# psoc4100tp register map
Vendor: Infineon Technologies; Series: PSOC4100Tp; File version: 1.0
CPU: CM0PLUS r0p1, little endian, no MPU, no FPU, VTOR, 2 interrupt priority bits
Registers are 32-bit, read-write, reset 0x0 unless marked. A register's access mark holds for its fields unless they carry their own. Offsets are from the block's base; [hi:lo] are bit positions; lines under a group give offsets from that group; {n}, {i} and the like mark numbered series; 'fields as' and 'values as' point back to an identical list; <NAME> marks a mode.

## MSCLP0 — Low Power MultiSense Converter
Base 0x40290000
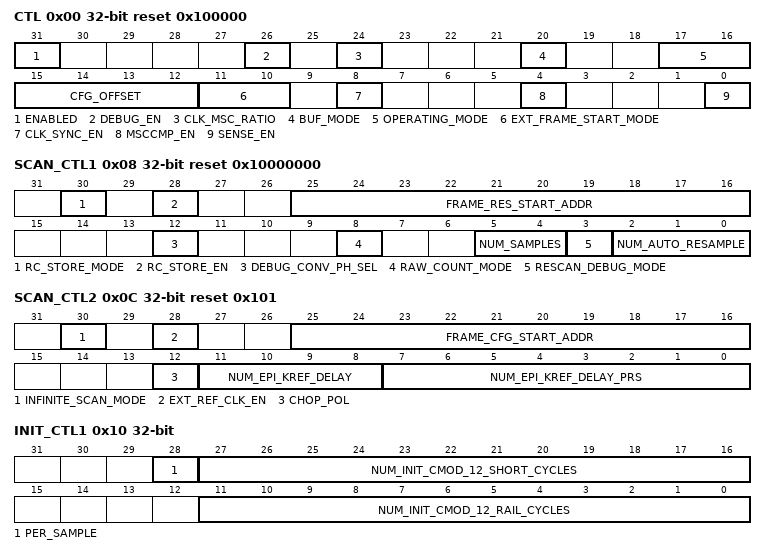
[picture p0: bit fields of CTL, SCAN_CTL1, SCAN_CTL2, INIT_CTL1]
0x00 CTL reset 0x100000 — Configuration and Control
  [31] ENABLED — Master enable of the MSCLP IP. Must be set to '1' for any operation to function. When '0' all analog components are off and all switches are open.
    0=DISABLED (N/A); 1=ENABLED (N/A)
  [26] DEBUG_EN
    0=DISABLED (N/A); 1=ENABLED (N/A)
  [24] CLK_MSC_RATIO — Control bit for logic that creates clk_msc from clk_hf. '0': Divided. clk_hf :: clk_msc is at least 2:1 divide ratio. Ratio controlled by clock_msc_pos_en and clock_msc_neg_en provided by PERI. '1': Pass-through. clk_hf :: clk_msc is 1:1.
    0=DIVIDED (N/A); 1=PASSTHROUGH (N/A)
  [20] BUF_MODE
    0=HIGH_BW_MODE (N/A); 1=SHIELD_MODE (N/A)
  [17:16] OPERATING_MODE
    0=CPU (Frame scan configurations are stored in system RAM. Start of frame initiated by CPU via AHB (typically using FRAME_CMD.START_FRAME) or an external frame start. After each scan in frame, the end of scan interrupt is raised. The CPU extracts results and programs and starts the next scan. ...); 1=CS_DMA (Frame scan configurations are stored in system RAM. Start of frame is initiated by CPU via AHB (typically using FRAME_CMD.START_FRAME) or an external frame start. MSCv3LP requests DMA to write each scan configuration and read each scan result....); 2=AS_MS (Frame scan configurations are stored in IP RAM. Start of frame initiated by CPU via AHB (expected to be FRAME_CMD.START_FRAME) or an external frame start. All of the scans in the frame are chained autonomously by Sequencer FSM. ...); 3=LP_AOS (Frame scan configurations are stored in IP RAM. Start of frame initiated by CPU via AHB (expected to be WAKEUP_CMD.START_FRAME_AOS) or an external frame start, and first frame starts after LP-AoS timer expire (as defined by WAKEUP_TIMER). Each scan in frame is chained autonomously by Sequencer FSM....)
  [15:12] CFG_OFFSET — Starting 32-bit word address offset index from SNS_LP_AOS_SNS_CTL0 register for each sensor configuration structure in local IP storage SENSOR_DATA. The difference between this CFG_OFFSET index and the index of SNS_CTL (index of 0xd addresses from SNS_LP_AOS_SNS_CTL0) defines the size of each configuration structure in SENSOR_DATA and the group of registers that change autonomously from sensor to sensor when scanning in AS_MS or LP_AOS modes. This setting is used by hardware when reading from local memory and programming IP registers - the logic will load from the memory from this starting offset and store into the SNS_* registers up to and including SNS_CTL. For example, setting this value to 0xb means that each configuration structure starts from SNS_SCAN_CTL (and all SNS_* registers up to and including SNS_CTL, so the configuration structure in SENSOR_DATA is 3x 32-bit words per sensor). Firmware Rule: If using AS_MS/LP_AOS mode and engaging the Channel Engine (CE_CTL.ENABLED = 1), then CFG_OFFSET must be set to 0x0 since the Channel Engine related registers are offset from here (SNS_LP_AOS_SENSOR_CTL0).
  [11:10] EXT_FRAME_START_MODE — Control to enable external frame start via GPIO. '0': External frame start capability off. Only START_FRAME or START_FRAME_AOS may be used to start frames. '1': External frame start capability on for frames where firmware is responsible for enabling MRSS. '2': External frame start capability on for low power frame where hardware is responsible for enabling MRSS.
    0=DISABLED (N/A); 1=EXT_FRAME_SCAN (N/A); 2=EXT_FRAME_LP_SCAN (N/A)
  [8] CLK_SYNC_EN — Control bit to create external channel sync clock. Used for multi-chip operation. '0': External synchronisation clock tied 0. '1': Generate external synchronisation clock using CLOCK_SYNC_DIV from the MRSS IMO.
    0=DISABLED (N/A); 1=ENABLED (N/A)
  [4] MSCCMP_EN — MSCLP Comparator Enable
    0=DISABLED (N/A); 1=ENABLED (N/A)
  [0] SENSE_EN
    0=DISABLED (N/A); 1=ENABLED (N/A)
0x04 SPARE — Spare MMIO
  [5:0] SPARE
0x08 SCAN_CTL1 reset 0x10000000 — Scan Control 1
  [30] RC_STORE_MODE
    0=STOP_ON_FULL (N/A); 1=WRAP (N/A)
  [28] RC_STORE_EN
    0=DISABLED (N/A); 1=ENABLED (N/A)
  [25:16] FRAME_RES_START_ADDR
  [12] DEBUG_CONV_PH_SEL
  [8] RAW_COUNT_MODE
    0=SATURATE (N/A); 1=OVERFLOW (N/A)
  [5:4] NUM_SAMPLES
  [3] RESCAN_DEBUG_MODE
    0=DISABLED (N/A); 1=ENABLED (N/A)
  [2:0] NUM_AUTO_RESAMPLE
0x0C SCAN_CTL2 reset 0x101 — Scan Control 2
  [30] INFINITE_SCAN_MODE — DFT bit that has the effect of keeping the Sequencer FSM in sub-converting forever to allow test measurements. With this bit set, the FSM remains sub-converting once entered. The only way to exit from this state is via a soft reset of the block via CTL.ENABLED. Firmware Rule: If used, must be followed up with a soft reset using CTL.ENABLED when measurements complete.
    0=DISABLED (N/A); 1=ENABLED (N/A)
  [28] EXT_REF_CLK_EN — Control whether the clock used for external Cref clocking is enabled. Firmware Rule: Must be enabled if any sensor is programmed to use external Cref clocking.
    0=DISABLED (N/A); 1=ENABLED (N/A)
  [25:16] FRAME_CFG_START_ADDR
  [12] CHOP_POL
  [11:8] NUM_EPI_KREF_DELAY — The duration of EPILOGUE defined in relation to Kref when (LFSR_MODE != PRS). The value is interpreted as Kref/4 increments. Duration of EPILOGUE calculated as: T_PRO_WAIT = NUM_EPI_KREF_DELAY*CEIL[(Kref)/4] This allows a range of [1, 15] which translates to [0.25Kref, 3.75Kref]. Firmware Rule: Note that setting this register to 0 is an illegal configuration. Recommended programming value is 2.
    1=MIN (N/A)
  [7:0] NUM_EPI_KREF_DELAY_PRS — The duration of EPILOGUE defined in relation to Kref when (LFSR_MODE = PRS). The value is interpreted as Kref/4 increments. Kref is defined via SENSE_DIV. Duration of EPILOGUE calculated as: T_PRO_WAIT = NUM_EPI_KREF_DELAY_PRS*CEIL[(Kref)/4] This allows a range of [1, 255] which translates to [0.25Kref, 63.75Kref]. Firmware Rule: Note that setting this register to 0 is an illegal configuration. Recommended programming value is 96.
0x10 INIT_CTL1 — Initialisation Control 1
  [28] PER_SAMPLE
    0=DISABLED (N/A); 1=ENABLED (N/A)
  [27:16] NUM_INIT_CMOD_12_SHORT_CYCLES — Duration of the coarse short phase (shorting Cmod1 and Cmod2 in full-wave mode). Programmed in terms of Fmod cycles. Firmware Rule: Should be set to zero in the case of half-wave mode.
  [11:0] NUM_INIT_CMOD_12_RAIL_CYCLES — Duration of the coarse initialisation phase (e.g. connecting Cmod1 to vdda and Cmod2 to vssa in full-wave mode). Programmed in terms of Fmod cycles.
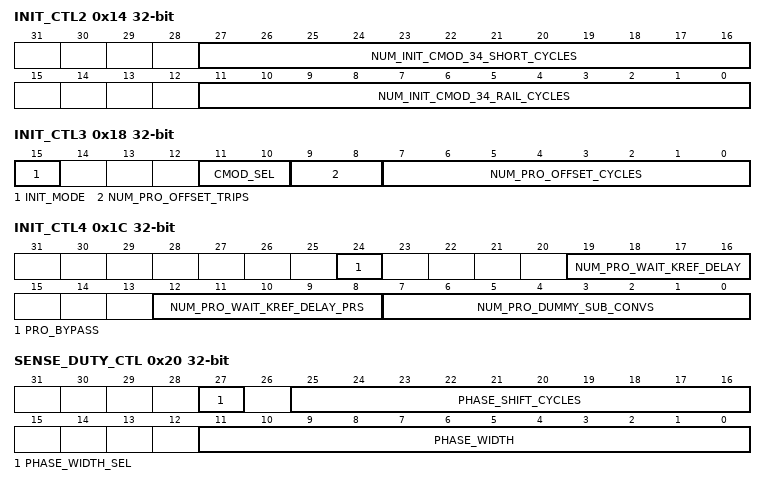
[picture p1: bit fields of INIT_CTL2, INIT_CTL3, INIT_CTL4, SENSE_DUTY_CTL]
0x14 INIT_CTL2 — Initialisation Control 2
  [27:16] NUM_INIT_CMOD_34_SHORT_CYCLES — Duration of the coarse short phase (shorting Cmod3 and Cmod4 in full-wave mode). Programmed in terms of Fmod cycles. Firmware Rule: Should be set to zero in the case of half-wave mode.
  [11:0] NUM_INIT_CMOD_34_RAIL_CYCLES — Duration of the coarse initialisation phase (e.g. connecting Cmod3 to vdda and Cmod4 to vssa in full-wave mode). Programmed in terms of Fmod cycles.
0x18 INIT_CTL3 — Initialisation Control 3
  [15] INIT_MODE — Determines autonomous initialisation behaviour during INIT_CMOD. Firmware Rule: In the case INIT_MODE = REFERENCE_VREF, firmware should also close CBSO, FSP and one of BGRF/RMF/MBF to select type of reference.
    0=REFERENCE_VDDA (Used for full and half wave when Vdda is reference.); 1=REFERENCE_VREF (Used for half-wave when Vref is reference.)
  [11:10] CMOD_SEL — Select which Cmod are used and the cycle thresholds to be used for coarse initialisation. Firmware Rule: Firmware must set a valid INIT_MODE with CMOD_SEL.
    0=CMOD_12 (Used for full-wave); 1=CMOD_34 (Used for full-wave); 2=CMOD_1 (Used for half-wave); 3=CMOD_3 (Used for half-wave)
  [9:8] NUM_PRO_OFFSET_TRIPS
  [7:0] NUM_PRO_OFFSET_CYCLES — Maximum number of Fmod cycles to be assigned for the PRO_OFFSET state. If NUM_PRO_OFFSET_TRIPS are observed before this timeout, exit at that point. Firmware Rule: If PRO_OFFSET is being used (either NUM_PRO_OFFSET_CYCLES != 0 or NUM_PRO_OFFSET_TRIPS != 0), SEL_CO_PRO_OFFSET must be > 0.
0x1C INIT_CTL4 — Initialisation Control 4
  [24] PRO_BYPASS
    0=DISABLED (N/A); 1=ENABLED (N/A)
  [19:16] NUM_PRO_WAIT_KREF_DELAY
  [12:8] NUM_PRO_WAIT_KREF_DELAY_PRS
  [7:0] NUM_PRO_DUMMY_SUB_CONVS
0x20 SENSE_DUTY_CTL — Sense Clock Duty Cycle Control
  [27] PHASE_WIDTH_SEL
    0=PH0_AND_PH2 (N/A); 1=PH1_AND_PH3 (N/A)
  [25:16] PHASE_SHIFT_CYCLES
  [11:0] PHASE_WIDTH — Control width (Fmod cycles) of ph0 and ph2 OR ph1 and ph3. If set to zero, Fs is divided equally between all phases. This field is only applicable when LFSR_MODE = DIRECT_CLOCK.
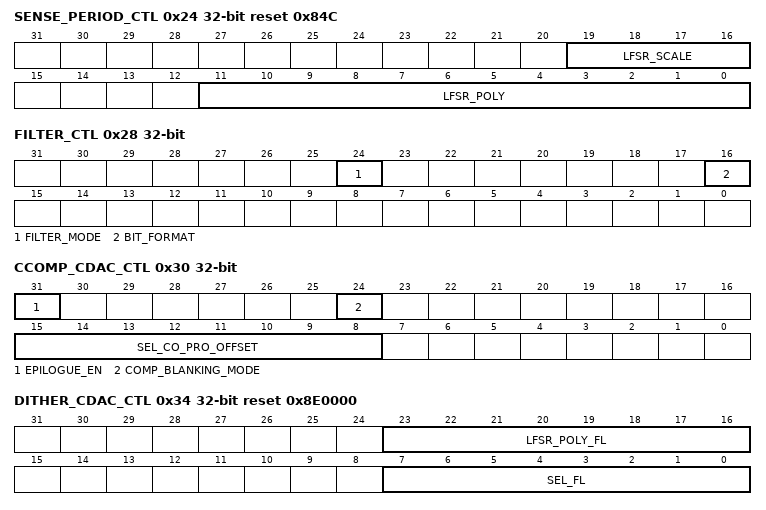
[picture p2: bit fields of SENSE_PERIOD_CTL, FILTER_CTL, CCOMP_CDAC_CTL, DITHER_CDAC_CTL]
0x24 SENSE_PERIOD_CTL reset 0x84C — Sense Clock Period Control
  [19:16] LFSR_SCALE
  [11:0] LFSR_POLY — Programmable polynomial to be used for the sense LFSR. For example (default): G(x) = X^12 + X^7 + X^4 + X^3 + 1 LFSR_POLY = 0x84C (1000_0100_1100). Note that LFSR_POLY[i] = 1 if X^(i+1) is included in the polynomial. The +1 feedback term is implied and doesn't need a programmable bit.
0x28 FILTER_CTL — Filter Control
  [24] FILTER_MODE
    0=CIC1 (Use the standard first order counter low pass filter (equivalent to CIC1).); 1=CIC2 (Use CIC2 Filter. Advantage of CIC2 over CIC1 is a higher resolution result for an equivalent scan time. All valid sub-samples are averaged to achieve an overall sample result for the scan. Interrupt is fired for every valid sub-sample to facilitate debug of the individual sub-samples.)
  [16] BIT_FORMAT
    0=UNSIGNED (Input values [0,+1]); 1=SIGNED (Input values [-1,+1]. In this scenario a value of 0 is interpreted as -1.)
0x30 CCOMP_CDAC_CTL — Compensation CAPDAC Control
  [31] EPILOGUE_EN
    0=DISABLED (N/A); 1=ENABLED (N/A)
  [24] COMP_BLANKING_MODE
    0=COMP_EN_25 (N/A); 1=COMP_EN_50 (N/A)
  [15:8] SEL_CO_PRO_OFFSET
0x34 DITHER_CDAC_CTL reset 0x8E0000 — Flatspot/Dither CAPDAC Switch Control
  [23:16] LFSR_POLY_FL — Dither/Flatspot CAPDAC LFSR polynomial. Uses same encoding as the spread spectrum polynomial LFSR_POLY. For example (default): G(x) = X^8 + X^4 + X^3 + X^2 + 1 LFSR_POLY_FL = 0x8E (1000_1110). Note that LFSR_POLY_FL[i] = 1 if X^(i+1) is included in the polynomial. The +1 feedback term is implied and doesn't need a programmable bit.
  [7:0] SEL_FL — Select value for Dither/Flatspot CAPDAC size. If dithering is enabled (FL_MODE = DITHER), this is the seed value for the LFSR. If FL_MODE = OFFSET, this value is presented directly to the hard IP as the CAPDAC code. If FL_MODE = OFF, this value is ignored and 0x00 is presented to the hard IP. Firmware Rule: If FL_MODE = DITHER, SEL_FL != 0 since it seeds the LFSR. Likely default seed is 0xFF.
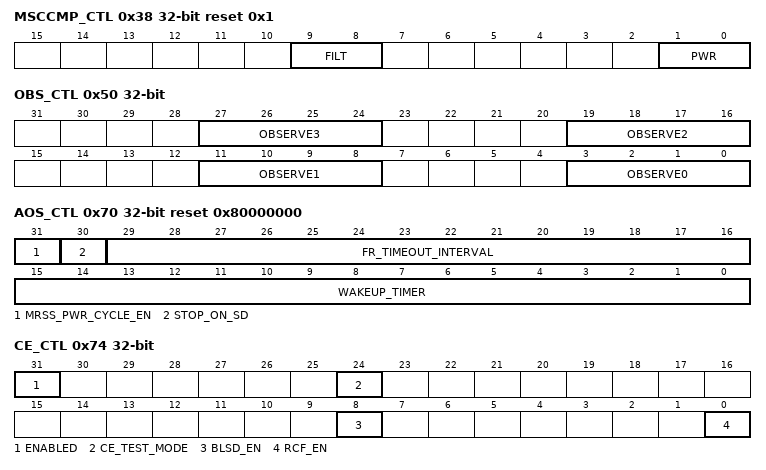
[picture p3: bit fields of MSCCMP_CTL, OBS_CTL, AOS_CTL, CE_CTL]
0x38 MSCCMP_CTL reset 0x1 — MSC Comparator Control
  [9:8] FILT — MSCLP comparator filter frequency select (corner frequencies - 90 percent settling). Firmware Guideline: Recommend 290MHz when Fmod = 46MHz, 115/64 Mhz if Fmod = 25MHz and 46MHz for any lower Fmod frequency.
    0=FREQ_290MHZ (N/A); 1=FREQ_115MHZ (N/A); 2=FREQ_64MHZ (N/A); 3=FREQ_46MHZ (N/A)
  [1:0] PWR — Power control setting on MSCLP comparator to allow noise reduction at the cost of current consumption (less noise, more power).
    0=X_0P5 (N/A); 1=N/A; 2=X_1P5 (N/A); 3=X_2 (N/A)
0x50 OBS_CTL — Observability Control
  [8n+3:8n] OBSERVE{n} (n=0..3)
    0=FS (N/A); 1=COMP_OUT (N/A); 2=COMP_OUT_ADV (N/A); 3=COMP_OUT_SYNC (N/A); 4=COUNTER_LSB (N/A); 5=SCAN_DONE (N/A); {v}=PH{v-6} (N/A) (v=6..9); 10=PH0X (N/A); 11=PH1X (N/A); 12=COMP_CLK_ENABLED (N/A); 13=UNUSED_1 (N/A); 14=SM_STATE_4 (N/A); 15=SM_STATE_{n} (N/A)
0x70 AOS_CTL reset 0x80000000 — Always On Scanning Control
  [31] MRSS_PWR_CYCLE_EN — Control bit to enable/disable hardware controlled power cycling of MRSS resources (reference, IMO, pump). This power cycling occurs at the end of frames initiated via FRAME_START_AOS that do not result in an interrupt. By default this is enabled to achieve maximum power savings. Note that independent of MRSS_PWR_CYCLE_EN, the MSCLP analog circuit is also disabled at the same time as the MRSS (even though CTL.ENABLED = 1). This autonomous disabling of the hard IP has the same effect as CTL.ENABLED = 0. Firmware Rule: Hardware power cycling must be disabled if firmware intends on accessing any MMIO in SNS_STRUCTLP during a time window when the AoS FSM is active. This is because the MMIO on SNS_STRUCTLP are clocked on the local IMO. If an access to this MMIO bank occurs while the IMO is power cycled, the transaction will be lost and the bridge cannot respond to this transaction.
    0=DISABLED (N/A); 1=ENABLED (N/A)
  [30] STOP_ON_SD
    0=DISABLED (N/A); 1=ENABLED (N/A)
  [29:16] FR_TIMEOUT_INTERVAL
  [15:0] WAKEUP_TIMER
0x74 CE_CTL — Channel Engine Control
  [31] ENABLED
    0=DISABLED (N/A); 1=ENABLED (N/A)
  [24] CE_TEST_MODE
    0=FUNCTIONAL_MODE (N/A); 1=TEST_MODE (N/A)
  [8] BLSD_EN
    0=DISABLED (N/A); 1=ENABLED (N/A)
  [0] RCF_EN
    0=DISABLED (N/A); 1=ENABLED (N/A)
0x80 PUMP_CTL — Local MRSS Pump Control
  [0] PUMP_MODE
    0=BYPASSED (Bypass the local pump (used when vdda > 4V).); 1=USED (Use the local pump (used when vdda < 4V).)
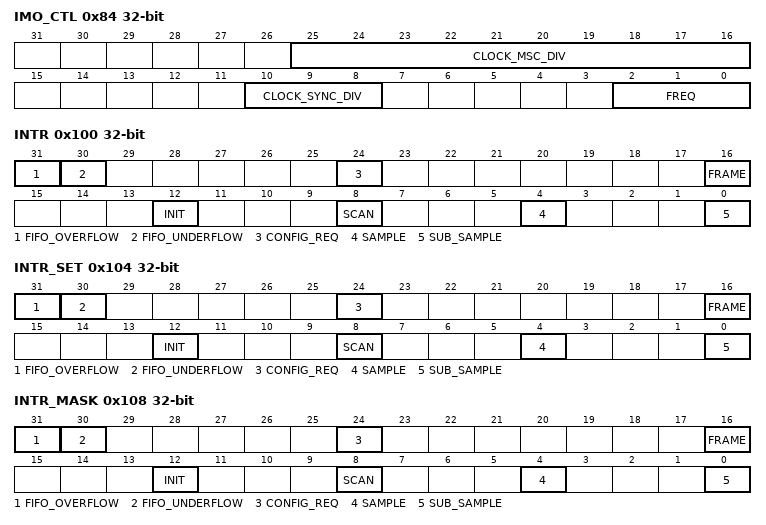
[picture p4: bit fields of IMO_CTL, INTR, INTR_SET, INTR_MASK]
0x84 IMO_CTL — Local MRSS IMO Control
  [25:16] CLOCK_MSC_DIV — Clock division ratio for clk_imo_msc to clk_msc. This specifies the frequency at which the main MSCLP digital is running at (clk_msc) and is equivalent to the modulator clock (clk_mod which runs at Fmod frequency). Note that CLOCK_REF_RATE defines the relationship of clk_ref to clk_mod.
  [10:8] CLOCK_SYNC_DIV
    {v}=DIV_BY_{v+1} (N/A) (v=0..7)
  [2:0] FREQ
    0=25_MHZ (IMO runs at 25 MHz); 1=28_MHZ (IMO runs at 28 MHz); 2=32_MHZ (IMO runs at 32 MHz); 3=38_MHZ (IMO runs at 38 MHz); 4=40_MHZ (IMO runs at 40 MHz); 5=44_MHZ (IMO runs at 44 MHz); 6=46_MHZ (IMO runs at 46 MHz)
0x100 INTR — MSCv3 Interrupt Cause Register
  [31] FIFO_OVERFLOW, [30] FIFO_UNDERFLOW, [24] CONFIG_REQ, [16] FRAME, [12] INIT, [8] SCAN, [4] SAMPLE, [0] SUB_SAMPLE
0x104 INTR_SET — MSCv3 Interrupt Set Register
  fields as INTR
0x108 INTR_MASK — MSCv3 Interrupt Mask Register
  fields as INTR
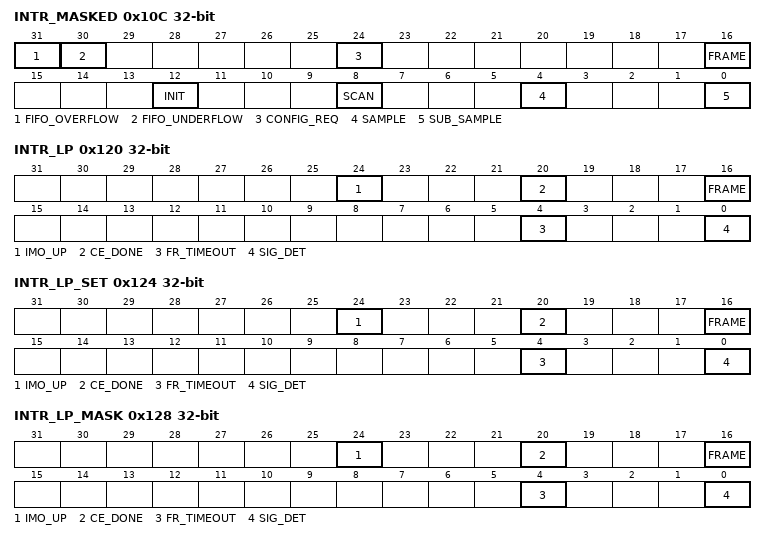
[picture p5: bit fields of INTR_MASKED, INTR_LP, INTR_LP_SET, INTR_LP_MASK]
0x10C INTR_MASKED ro — MSCv3 Interrupt Masked Register
  fields as INTR
0x120 INTR_LP — Low Power Interrupt Cause Register
  [24] IMO_UP — MSCLP logic has turned on the MRSS IMO. Firmware Rule: CTL.ENABLED = 0 does not reset the cause for this interrupt. This is because CTL.ENABLED must be 0 when booting up the MRSS via firmware. Once IMO_UP is detected, CTL.ENABLED can be set to 1 to release reset to tbe block synchronously to the newly started MRSS IMO.
  [20] CE_DONE
  [16] FRAME
  [4] FR_TIMEOUT
  [0] SIG_DET
0x124 INTR_LP_SET — Low Power Interrupt Set Register
  [24] IMO_UP, [20] CE_DONE, [16] FRAME, [4] FR_TIMEOUT, [0] SIG_DET
0x128 INTR_LP_MASK — Low Power Interrupt Mask Register
  [24] IMO_UP, [20] CE_DONE, [16] FRAME, [4] FR_TIMEOUT, [0] SIG_DET
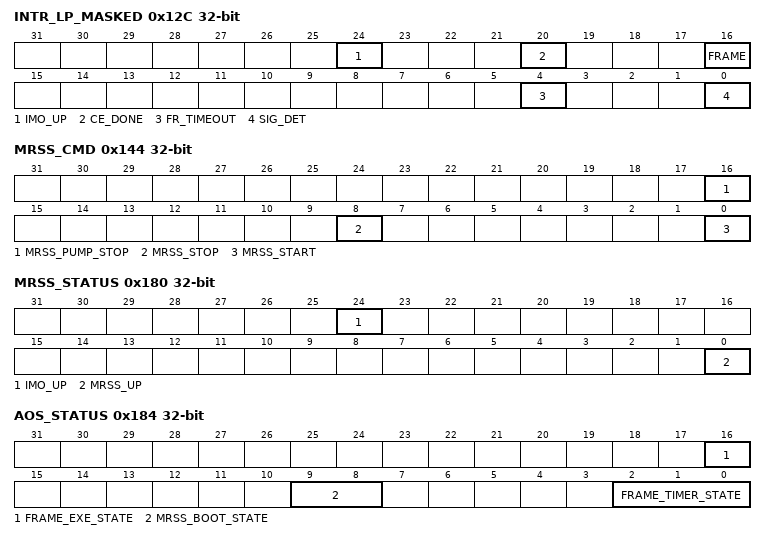
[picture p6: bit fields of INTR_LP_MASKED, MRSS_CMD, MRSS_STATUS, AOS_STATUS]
0x12C INTR_LP_MASKED ro — Low Power Interrupt Masked Register
  [24] IMO_UP, [20] CE_DONE, [16] FRAME, [4] FR_TIMEOUT, [0] SIG_DET
0x140 WAKEUP_CMD — Wakeup Command Register
  [0] START_FRAME_AOS
0x144 MRSS_CMD — MRSS Command Register
  [16] MRSS_PUMP_STOP — Stop the MRSS pump resource. The ability to shut off the MRSS pump allows for power saving when MSCLP is in a standby state (CTL.ENABLED = 0) not scanning and hence no pump is needed. In this case the MRSS reference and IMO remain on so firmware may access MMIO in the SNS_STRUCTLP register bank. MRSS_STOP is used in the case where the entire MRSS is to be shut down.
  [8] MRSS_STOP
  [0] MRSS_START
0x180 MRSS_STATUS ro
  [24] IMO_UP, [0] MRSS_UP
0x184 AOS_STATUS ro
  [16] FRAME_EXE_STATE — LP-AoS Frame Execute FSM state.
    0=IDLE (N/A); 1=LP_EXE_FRAME (N/A)
  [9:8] MRSS_BOOT_STATE — LP-AoS MRSS Boot FSM state.
    0=IDLE (N/A); 1=START_REF (N/A); 2=START_IMO (N/A); 3=START_PUMP (N/A)
  [2:0] FRAME_TIMER_STATE — LP-AoS Frame Timer FSM state.
    0=IDLE (N/A); 1=WAIT_FRAME_INTERVAL (N/A); 2=WAIT_IMO (N/A); 3=LP_START_FRAME (N/A); 4=LP_WAIT_FRAME (N/A)
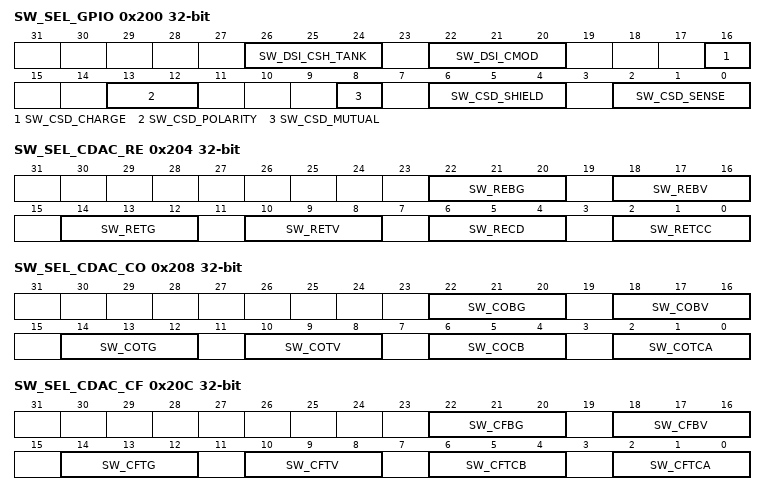
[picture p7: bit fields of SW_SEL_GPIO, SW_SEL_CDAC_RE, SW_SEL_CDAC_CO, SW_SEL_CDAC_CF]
0x200 SW_SEL_GPIO — GPIO Switch Control
  [26:24] SW_DSI_CSH_TANK — MUX select for dsi_csh_tank waveform.
    0=LOGIC_0 (N/A); 1=LOGIC_1 (N/A); 2=CHOP_PH0_PH1 (chop == 1 ? ph0 : ph1); 3=CHOP_PH1_PH3 (chop == 1 ? ph1 : ph3); 4=PH1 (N/A)
  [22:20] SW_DSI_CMOD — MUX select for dsi_cmod waveform.
    0=LOGIC_0 (N/A); 1=LOGIC_1 (N/A); 2=CHOP_PH1_PH0 (chop == 1 ? ph1 : ph0); 3=CHOP_PH3_PH1 (chop == 1 ? ph3 : ph1); 4=PH0 (N/A)
  [16] SW_CSD_CHARGE
    0=LOGIC_0 (N/A); 1=LOGIC_1 (N/A)
  [13:12] SW_CSD_POLARITY
    0=LOGIC_0 (N/A); 1=LOGIC_1 (N/A); 2=PH0_OR_PH1 (N/A)
  [8] SW_CSD_MUTUAL
    0=LOGIC_0 (N/A); 1=LOGIC_1 (N/A)
  [6:4] SW_CSD_SHIELD
    0=LOGIC_0 (N/A); 1=LOGIC_1 (N/A); 2=PH0 (N/A); 3=PH1 (N/A); 4=PH0_OR_PH3 (N/A); 5=PH0_OR_FS2PH1_AND_PH1_OR_PH3 (ph0 || [Fs2_ph1 && (ph1 || ph3)]); 6=PH1X (N/A)
  [2:0] SW_CSD_SENSE
    0=LOGIC_0 (N/A); 1=LOGIC_1 (N/A); 2=PH0 (N/A); 3=PH1 (N/A); 4=PH0_OR_PH3 (N/A); 5=PH0X (N/A); 6=PH1X (N/A)
0x204 SW_SEL_CDAC_RE — Reference CAPDAC Switch Control
  [22:20] SW_REBG — Reference CAPDAC bottom plate to vssa_q Switch. Firmware Rule: Do not program REBV and REBG such that they are closed simultaneously.
    0=OPEN (sel = 00); 1=CLOSED (sel = 01); 2=CLK (sel = 10 (clk_reffb)); 3=CLK_BAR (sel = 11 (!clk_reffb)); 4=PH1X (DFT mode (ph1X ? sel = 01 : sel = 00))
  [18:16] SW_REBV — Reference CAPDAC bottom plate to vdda_q Switch. Firmware Rule: Do not program REBV and REBG such that they are closed simultaneously.
    0=OPEN (sel = 00); 1=CLOSED (sel = 01); 2=CLK (sel = 10 (clk_reffb)); 3=CLK_BAR (sel = 11 (!clk_reffb)); 4=PH0X (DFT mode (ph0X ? sel = 01 : sel = 00))
  [14:12] SW_RETG
    0=OPEN (sel = 00); 1=CLOSED (sel = 01); 2=CLK (sel = 10 (clk_reffb)); 3=CLK_BAR (sel = 11 (!clk_reffb)); 4=PH0 (DFT mode (ph0 ? sel = 01 : sel = 00)); 5=PH2 (DFT mode (ph2 ? sel = 01 : sel = 00))
  [10:8] SW_RETV — Reference CAPDAC top plate to vdda_q Switch. Firmware Rule: Do not program RETV and RETG such that they are closed simultaneously.
    values as SW_RETG
  [6:4] SW_RECD — Reference CAPDAC to CSD Bus D Switch.
    0=OPEN (sel = 00); 1=CLOSED (sel = 01); 2=CHOP_CLK_BAR (chop == 0 ? sel = 10 (clk_reffb) : sel = 11 (!clk_reffb)); 3=CHOP_CLK (chop == 1 ? sel = 10 (clk_reffb) : sel = 11 (!clk_reffb)); 4=PH1 (DFT mode (ph1 ? sel = 01 : sel = 00)); 5=PH3 (DFT mode (ph3 ? sel = 01 : sel = 00))
  [2:0] SW_RETCC — Reference CAPDAC top plate to CSD Bus C Switch.
    0=OPEN (sel = 00); 1=CLOSED (sel = 01); 2=CHOP_CLK_BAR (chop == 0 ? sel = 10 (clk_reffb) : sel = 11 (!clk_reffb)); 3=CHOP_CLK (chop == 1 ? sel = 10 (clk_reffb) : sel = 11 (!clk_reffb)); 4=PH1 (DFT mode (ph1 ? sel = 01 : sel = 00)); 5=PH3 (DFT mode (ph3 ? sel = 01 : sel = 00)); 6=PH0 (DFT mode (ph0 ? sel = 01 : sel = 00))
0x208 SW_SEL_CDAC_CO — Compensation CAPDAC Switch Control
  [22:20] SW_COBG — Compensation CAPDAC bottom plate to vssa_q Switch. Firmware Rule: Do not program COBV and COBG such that they are closed simultaneously.
    0=OPEN (sel = 00); 1=CLOSED (sel = 01); 2=CLK (sel = 10 (clk_comp)); 3=CLK_BAR (sel = 11 (!clk_comp)); 4=PH1X (DFT mode (ph1X ? sel = 01 : sel = 00))
  [18:16] SW_COBV — Compensation CAPDAC bottom plate to vdda_q Switch. Firmware Rule: Do not program COBV and COBG such that they are closed simultaneously.
    0=OPEN (sel = 00); 1=CLOSED (sel = 01); 2=CLK (sel = 10 (clk_comp)); 3=CLK_BAR (sel = 11 (!clk_comp)); 4=PH0X (DFT mode (ph0X ? sel = 01 : sel = 00))
  [14:12] SW_COTG — Compensation CAPDAC top plate to vssa_q Switch. Firmware Rule: Do not program COTV and COTG such that they are closed simultaneously.
    values as SW_SEL_CDAC_RE.SW_RETG
  [10:8] SW_COTV — Compensation CAPDAC top plate to vdda_q Switch. Firmware Rule: Do not program COTV and COTG such that they are closed simultaneously.
    values as SW_SEL_CDAC_RE.SW_RETG
  [6:4] SW_COCB — Compensation CAPDAC to CSD Bus B Switch.
    0=OPEN (sel = 00); 1=CLOSED (sel = 01); 2=CHOP_CLK_BAR (chop == 0 ? sel = 10 (clk_comp) : sel = 11 (!clk_comp)); 3=CHOP_CLK (chop == 1 ? sel = 10 (clk_comp) : sel = 11 (!clk_comp)); 4=PH1 (DFT mode (ph1 ? sel = 01 : sel = 00)); 5=PH3 (DFT mode (ph3 ? sel = 01 : sel = 00))
  [2:0] SW_COTCA — Compensation CAPDAC top plate to CSD Bus A Switch.
    0=OPEN (sel = 00); 1=CLOSED (sel = 01); 2=CHOP_CLK_BAR (chop == 0 ? sel = 10 (clk_comp) : sel = 11 (!clk_comp)); 3=CHOP_CLK (chop == 1 ? sel = 10 (clk_comp) : sel = 11 (!clk_comp)); 4=PH1 (DFT mode (ph1 ? sel = 01 : sel = 00)); 5=PH3 (DFT mode (ph3 ? sel = 01 : sel = 00)); 6=PH0 (DFT mode (ph0 ? sel = 01 : sel = 00))
0x20C SW_SEL_CDAC_CF — Fine CAPDAC Switch Control
  [22:20] SW_CFBG — Fine CAPDAC bottom plate to vssa_q Switch. Firmware Rule: Do not program CFBV and CFBG such that they are closed simultaneously.
    0=OPEN (sel = 00); 1=CLOSED (sel = 01); 2=CLK (FINE_MODE == REFERENCE ? sel = 10 (clk_reffb) : sel = 10 (clk_comp)); 3=CLK_BAR (FINE_MODE == REFERENCE ? sel = 11 (!clk_reffb) : sel = 11 (!clk_comp)); 4=PH1X (DFT mode (ph1X ? sel = 01 : sel = 00))
  [18:16] SW_CFBV — Fine CAPDAC bottom plate to vdda_q Switch. Firmware Rule: Do not program CFBV and CFBG such that they are closed simultaneously.
    0=OPEN (sel = 00); 1=CLOSED (sel = 01); 2=CLK (FINE_MODE == REFERENCE ? sel = 10 (clk_reffb) : sel = 10 (clk_comp)); 3=CLK_BAR (FINE_MODE == REFERENCE ? sel = 11 (!clk_reffb) : sel = 11 (!clk_comp)); 4=PH0X (DFT mode (ph0X ? sel = 01 : sel = 00))
  [14:12] SW_CFTG — Fine CAPDAC top plate to vssa_q Switch. Firmware Rule: Do not program CFTV and CFTG such that they are closed simultaneously.
    0=OPEN (sel = 00); 1=CLOSED (sel = 01); 2=CLK (sel = 10 [(FINE_MODE == REFERENCE) ? clk_reffb : clk_comp]); 3=CLK_BAR (sel = 11 [(FINE_MODE == REFERENCE) ? !clk_reffb : !clk_comp]); 4=PH0 (DFT mode (ph0 ? sel = 01 : sel = 00)); 5=PH2 (DFT mode (ph2 ? sel = 01 : sel = 00))
  [10:8] SW_CFTV — Fine CAPDAC top plate to vdda_q Switch. Firmware Rule: Do not program CFTV and CFTG such that they are closed simultaneously.
    values as SW_CFTG
  [6:4] SW_CFTCB — Fine CAPDAC top plate to CSD Bus B Switch.
    0=OPEN (sel = 00); 1=CLOSED (sel = 01); 2=CHOP_CLK_BAR (case({chop,FINE_MODE}) {1,REFERENCE} : sel = 11 (!clk_reffb) {1,COMPENSATION} : sel = 11 (!clk_comp)...); 3=CHOP_CLK (case({chop,FINE_MODE}) {1,REFERENCE} : sel = 10 (clk_reffb) {1,COMPENSATION} : sel = 10 (clk_comp)...); 4=PH1 (DFT mode (ph1 ? sel = 01 : sel = 00)); 5=PH3 (DFT mode (ph3 ? sel = 01 : sel = 00)); 6=PH0 (DFT mode (ph0 ? sel = 01 : sel = 00))
  [2:0] SW_CFTCA — Fine CAPDAC top plate to CSD Bus A Switch.
    values as SW_CFTCB
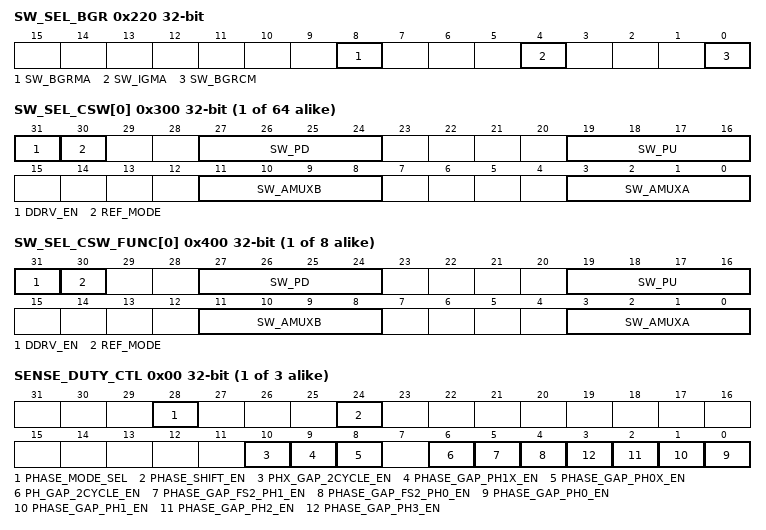
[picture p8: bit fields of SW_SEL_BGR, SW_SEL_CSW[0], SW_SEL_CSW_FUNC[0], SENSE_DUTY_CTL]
0x220 SW_SEL_BGR — Bandgap Reference Switch Control
  [all] fields
    0=OPEN (N/A); 1=CLOSED (N/A)
  [8] SW_BGRMA
  [4] SW_IGMA
  [0] SW_BGRCM
{0x300+4i} SW_SEL_CSW[{i}] (i=0..63) — CAPSENSE Sensor Switch Control
  [31] DDRV_EN — MultiSense GPIO Sensor N digital driver enable in MSCLP specific GPIO. Firmware Rule: When using the digital driver, the GPIO MSCLP analog cannot be used (GPIO port register MSC_ANA.DATAx for port pin x should be set 0).
    0=DISABLED (N/A); 1=ENABLED (N/A)
  [30] REF_MODE — MultiSense GPIO Sensor N is used as a reference.
    0=DISABLED (N/A); 1=ENABLED (N/A)
  [27:24] SW_PD — MultiSense GPIO Sensor N pull down to vssa_q Switch. Firmware Rule: Do not program PU and PD such that they are closed simultaneously.
    0=OPEN (N/A); 1=CLOSED (N/A); 2=PH0 (N/A); 3=PH1 (N/A); 4=PH2 (N/A); 5=PH1_OR_PH3 (N/A); 6=PH2_OR_PH3 (N/A); 7=PH0X (N/A); 8=PH1X (N/A); 9=PH2_OR_FS2PH1_AND_PH1_OR_PH3 (ph2 || [Fs2_ph1 && (ph1 || ph3)]); 10=CLK_BAR (clk_extfb_bar); 11=PH1_OR_PH2 (Note SENSE_DUTY_CTL digital non-overlap control has no impact on this waveform.); 12=PH0_OR_PH3 (Note SENSE_DUTY_CTL digital non-overlap control has no impact on this waveform.)
  [19:16] SW_PU — MultiSense GPIO Sensor N pull up to vdda_q Switch. Also drives the MSCLP specific GPIO digital driver (enable controlled by DDRV_EN). Firmware Rule: Do not program PU and PD such that they are closed simultaneously.
    0=OPEN (N/A); 1=CLOSED (N/A); 2=PH0 (N/A); 3=PH1 (N/A); 4=PH2 (N/A); 5=PH0_OR_PH1 (N/A); 6=PH0X (N/A); 7=PH1X (N/A); 8=PH0_OR_FS2PH0_AND_PH1_OR_PH3 (ph0 || [Fs2_ph0 && (ph1 || ph3)]); 9=CLK (clk_extfb); 10=PH0X_BAR; 11=PH1_OR_PH2 (Note SENSE_DUTY_CTL digital non-overlap control has no impact on this waveform.); 12=PH0_OR_PH3 (Note SENSE_DUTY_CTL digital non-overlap control has no impact on this waveform.)
  [11:8] SW_AMUXB — MultiSense GPIO Sensor N to AMUXBUSB Switch.
    0=OPEN (N/A); 1=CLOSED (N/A); 2=CHOP_TWO_PHASE (chop == 0 ? ph1 : ph0); 3=CHOP_FOUR_PHASE (chop == 0 ? ph3 : ph1); 4=CHOP_MPSC_D (chop == 0 ? ph1 : ph3); 5=CHOP_MPRX (chop == 0 ? ph0 : ph1); 6=PH0 (N/A); 7=PH2 (N/A); 8=CHOP_CLK_BAR (chop == 0 ? clk_extfb : clk_extfb_bar); 9=CHOP_CLK (chop == 1 ? clk_extfb : clk_extfb_bar); 10=PH1_OR_PH3 (N/A)
  [3:0] SW_AMUXA — MultiSense GPIO Sensor N to AMUXBUSA Switch.
    0=OPEN (N/A); 1=CLOSED (N/A); 2=CHOP_TWO_PHASE (chop == 0 ? ph0 : ph1); 3=CHOP_FOUR_PHASE (chop == 0 ? ph1 : ph3); 4=CHOP_MPSC_D (chop == 0 ? ph3 : ph1); 5=CHOP_MPRX (chop == 0 ? ph1 : ph0); 6=PH1 (N/A); 7=PH3 (N/A); 8=CHOP_CLK_BAR (chop == 0 ? clk_extfb : clk_extfb_bar); 9=CHOP_CLK (chop == 1 ? clk_extfb : clk_extfb_bar); 10=PH1_OR_PH3 (N/A)
{0x400+4i} SW_SEL_CSW_FUNC[{i}] (i=0..7) — CAPSENSE Sensor Switch Control Global Functions
  [31] DDRV_EN — MultiSense GPIO Sensor N digital driver enable in MSCLP specific GPIO. Firmware Rule: When using the digital driver, the GPIO MSCLP analog cannot be used (GPIO port register MSC_ANA.DATAx for port pin x should be set 0).
    0=DISABLED (N/A); 1=ENABLED (N/A)
  [30] REF_MODE — MultiSense GPIO Sensor is used as a reference.
    0=DISABLED (N/A); 1=ENABLED (N/A)
  [27:24] SW_PD — MultiSense GPIO Sensor pull down to vssa_q Switch. Firmware Rule: Do not program PU and PD such that they are closed simultaneously.
    values as SW_SEL_CSW[0].SW_PD
  [19:16] SW_PU — MultiSense GPIO Sensor pull up to vdda_q Switch. Also drives the MSCLP specific GPIO digital driver (enable controlled by DDRV_EN). Firmware Rule: Do not program PU and PD such that they are closed simultaneously.
    values as SW_SEL_CSW[0].SW_PU
  [11:8] SW_AMUXB — MultiSense GPIO Sensor N to AMUXBUSB Switch.
    values as SW_SEL_CSW[0].SW_AMUXB
  [3:0] SW_AMUXA — MultiSense GPIO Sensor to AMUXBUSA Switch.
    values as SW_SEL_CSW[0].SW_AMUXA
0x500 CSW_CTL_LO — CAPSENSE Sensor Switch Control Low
  [31:0] CSW_FUNC_MODE
0x504 CSW_CTL_HI — CAPSENSE Sensor Switch Control High
  [31:0] CSW_FUNC_MODE
{0x600+0x40*i} MODE[{i}] (i=0..2) group — Sense Mode Configuration Structure
  0x00 SENSE_DUTY_CTL — Sense Clock Duty Cycle Control
    [28] PHASE_MODE_SEL
      0=FOUR_PHASE (N/A); 1=TWO_PHASE (N/A)
    [24] PHASE_SHIFT_EN
      0=DISABLED (N/A); 1=ENABLED (N/A)
    [10] PHX_GAP_2CYCLE_EN
      0=ONE_CYCLE (N/A); 1=TWO_CYCLE (N/A)
    [9] PHASE_GAP_PH1X_EN — Decide whether clk_mod cycle non-overlap gap is applied at the end of ph1x. PHASE_GAP_PH1X_EN = 0 -> No gap. PHASE_GAP_PH1X_EN = 1 && PHX_GAP_2CYCLE_EN = 0 -> 1x cycle gap. PHASE_GAP_PH1X_EN = 1 && PHX_GAP_2CYCLE_EN = 1 -> 2x cycle gap.
      0=DISABLED (N/A); 1=ENABLED (N/A)
    [8] PHASE_GAP_PH0X_EN — Decide whether clk_mod cycle non-overlap gap is applied at the end of ph0x. PHASE_GAP_PH0X_EN = 0 -> No gap. PHASE_GAP_PH0X_EN = 1 && PHX_GAP_2CYCLE_EN = 0 -> 1x cycle gap. PHASE_GAP_PH0X_EN = 1 && PHX_GAP_2CYCLE_EN = 1 -> 2x cycle gap.
      0=DISABLED (N/A); 1=ENABLED (N/A)
    [6] PH_GAP_2CYCLE_EN
      0=ONE_CYCLE (N/A); 1=TWO_CYCLE (N/A)
    [5] PHASE_GAP_FS2_PH1_EN — Decide whether clk_mod cycle non-overlap gap is applied at the end of Fs2_ph0. PHASE_GAP_FS2_PH1_EN = 0 -> No gap. PHASE_GAP_FS2_PH1_EN = 1 && PH_GAP_2CYCLE_EN = 0 -> 1x cycle gap. PHASE_GAP_FS2_PH1_EN = 1 && PH_GAP_2CYCLE_EN = 1 -> 2x cycle gap.
      0=DISABLED (N/A); 1=ENABLED (N/A)
    [4] PHASE_GAP_FS2_PH0_EN — Decide whether clk_mod cycle non-overlap gap is applied at the end of Fs2_ph0. PHASE_GAP_FS2_PH0_EN = 0 -> No gap. PHASE_GAP_FS2_PH0_EN = 1 && PH_GAP_2CYCLE_EN = 0 -> 1x cycle gap. PHASE_GAP_FS2_PH0_EN = 1 && PH_GAP_2CYCLE_EN = 1 -> 2x cycle gap.
      0=DISABLED (N/A); 1=ENABLED (N/A)
    [n] PHASE_GAP_PH{n}_EN (n=0..3) — Decide whether clk_mod cycle non-overlap gap is applied at the end of ph{n}. PHASE_GAP_PH{n}_EN = 0 -> No gap. PHASE_GAP_PH{n}_EN = 1 && PH_GAP_2CYCLE_EN = 0 -> 1x cycle gap. PHASE_GAP_PH{n}_EN = 1 && PH_GAP_2CYCLE_EN = 1 -> 2x cycle gap.
      0=DISABLED (N/A); 1=ENABLED (N/A)
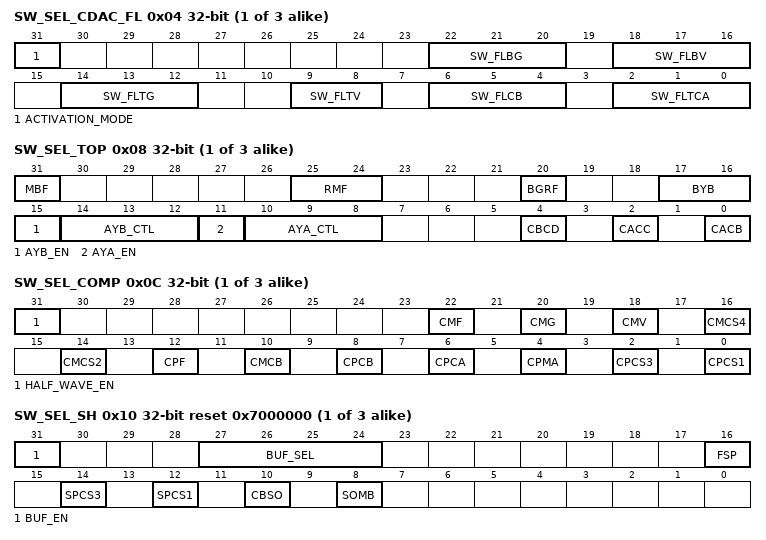
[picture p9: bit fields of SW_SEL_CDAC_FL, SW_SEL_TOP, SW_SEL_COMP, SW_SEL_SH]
  0x04 SW_SEL_CDAC_FL — Flatspot/Dither CAPDAC Switch Control
    [31] ACTIVATION_MODE — Activation event for Dither/Flatspot LFSR. '0': Clock LFSR on ph0. '1': Clock LFSR on ph0 or ph2.
      0=PH0 (N/A); 1=PH0_OR_PH2 (N/A)
    [22:20] SW_FLBG — Flatspot/Dither CAPDAC bottom plate to vssa_q Switch. Firmware Rule: Do not program FLBV and FLBG such that they are closed simultaneously.
      0=OPEN (N/A); 1=CLOSED (N/A); 2=PH0X (N/A); 3=PH1X (N/A); 4=PRECHARGE_2_PH ([(msb^ph1)^(ph0||ph1)] & [ph0||ph1]); 5=PRECHARGE_2_PH_BAR ((![(msb^ph1)^(ph0||ph1)]) & [ph0||ph1]); 6=PRECHARGE_4_PH ([(msb^(ph2||ph3))^(ph0||ph2)] & [ph0||ph1||ph2||ph3]); 7=PRECHARGE_4_PH_BAR ((![(msb^(ph2||ph3))^(ph0||ph2)]) & [ph0||ph1||ph2||ph3])
    [18:16] SW_FLBV — Flatspot/Dither CAPDAC bottom plate to vdda_q Switch. Firmware Rule: Do not program FLBV and FLBG such that they are closed simultaneously.
      values as SW_FLBG
    [14:12] SW_FLTG — Flatspot/Dither CAPDAC top plate to vssa_q Switch. Firmware Rule: Do not program FLTV and FLTG such that they are closed simultaneously.
      0=OPEN (N/A); 1=CLOSED (N/A); 2=PH1 (N/A); 3=PH0_OR_PH2 (N/A); 4=PH0 (DFT mode); 5=PH2 (DFT mode)
    [9:8] SW_FLTV — Flatspot/Dither CAPDAC top plate to vdda_q Switch. Firmware Rule: Do not program FLTV and FLTG such that they are closed simultaneously.
      0=OPEN (N/A); 1=CLOSED (N/A); 2=PH0 (DFT mode); 3=PH2 (DFT mode)
    [6:4] SW_FLCB — Flatspot/Dither CAPDAC to CSD Bus B Switch.
      0=OPEN (N/A); 1=CLOSED (N/A); 2=CHOP_PH1_4PHASE (chop == 1 ? ph1 : ph3); 3=CHOP_PH3 (chop == 1 ? ph3 : ph1); 4=CHOP_PH0 (chop == 1 ? ph0 : ph1); 5=CHOP_PH1_2PHASE (chop == 1 ? ph1 : ph0)
    [2:0] SW_FLTCA — Flatspot/Dither CAPDAC top plate to CSD Bus A Switch.
      values as SW_FLCB
  0x08 SW_SEL_TOP — Top Level Switch Control
    [31] MBF
      0=OPEN (N/A); 1=CLOSED (N/A)
    [25:24] RMF
      0=OFF (Resistor divider off.); 1=VDDA_X_0P5 (vdda/2); 2=VDDA_X_0P3 (vdda*0.3 (Used to detect when vdda=4V then resistor divider will output 1.2V)); 3=VDDA_X_0P8 (vdda*0.8)
    [20] BGRF
      0=OPEN (N/A); 1=CLOSED (N/A)
    [17:16] BYB — AMUXBUS B to CSD Bus B Switch.
      0=OPEN_ISOLATED (sel = 00); 1=OPEN_NON_ISOLATED_CSDBUS (sel = 01); 2=OPEN_NON_ISOLATED_AMUXBUS (sel = 10); 3=CLOSED (sel = 11)
    [15] AYB_EN — AMUXBUS A to CSD Bus B Switch. Controls first part of AYB switch (AYB_EN<0> on the hardIP).
      0=OPEN_ISOLATED (Opens first part of AYB switch. Enables isolation on AYB if AYB_CTL is also OPEN.); 1=CLOSED (Closes first part of AYB switch and disables isolation.)
    [14:12] AYB_CTL — AMUXBUS A to CSD Bus B Switch. Controls second part of AYB switch (AYB_EN<1> on hardIP).
      0=OPEN (Opens second part of AYB switch. Enables isolation on AYB if AYB_EN is also OPEN_ISOLATED.); 1=CLOSED (N/A); 2=CHOP_TWO_PHASE (chop == 0 ? ph1 : ph0); 3=CHOP_FOUR_PHASE (chop == 0 ? ph3 : ph1); 4=CHOP_MPSC_D (chop == 0 ? ph1 : ph3); 5=CHOP_MPRX (chop == 0 ? ph0 : ph1); 6=PH0 (N/A); 7=PH2 (N/A)
    [11] AYA_EN — AMUXBUS A to CSD Bus A Switch. Controls the first part of AYA switch (AYA_EN<0> on the hardIP).
      0=OPEN_ISOLATED (Opens first part of AYA switch. Enables isolation on AYA if AYA_CTL is also OPEN.); 1=CLOSED (Closes first part of AYA switch and disables isolation.)
    [10:8] AYA_CTL — AMUXBUS A to CSD Bus A Switch. Controls second part of AYA switch (AYA_EN<1> on hardIP).
      0=OPEN (Opens second part of AYA switch. Enables isolation on AYA if AYA_EN is also OPEN_ISOLATED.); 1=CLOSED (N/A); 2=CHOP_TWO_PHASE (chop == 0 ? ph0 : ph1); 3=CHOP_FOUR_PHASE (chop == 0 ? ph1 : ph3); 4=CHOP_MPSC_D (chop == 0 ? ph3 : ph1); 5=CHOP_MPRX (chop == 0 ? ph1 : ph0); 6=PH0 (N/A); 7=PH2 (N/A)
    [4] CBCD — CSD Bus B to CSD Bus D Switch.
      0=OPEN (N/A); 1=CLOSED (N/A)
    [2] CACC — CSD Bus A to CSD Bus C Switch.
      0=OPEN (N/A); 1=CLOSED (N/A)
    [0] CACB — CSD Bus A to CSD Bus B Switch.
      0=OPEN (N/A); 1=CLOSED (N/A)
  0x0C SW_SEL_COMP — MSC Comparator Switch Control
    [31] HALF_WAVE_EN
      0=DISABLED (N/A); 1=ENABLED (N/A)
    [22] CMF
      0=OPEN (N/A); 1=CLOSED (N/A)
    [20] CMG
      0=OPEN (N/A); 1=CLOSED (N/A)
    [18] CMV
      0=OPEN (N/A); 1=CLOSED (N/A)
    [16] CMCS4
      0=OPEN (N/A); 1=CLOSED (N/A)
    [14] CMCS2
      0=OPEN (N/A); 1=CLOSED (N/A)
    [12] CPF
      0=OPEN (N/A); 1=CLOSED (N/A)
    [10] CMCB
      0=OPEN (N/A); 1=CLOSED (N/A)
    [8] CPCB
      0=OPEN (N/A); 1=CLOSED (N/A)
    [6] CPCA
      0=OPEN (N/A); 1=CLOSED (N/A)
    [4] CPMA
      0=OPEN (N/A); 1=CLOSED (N/A)
    [2] CPCS3
      0=OPEN (N/A); 1=CLOSED (N/A)
    [0] CPCS1
      0=OPEN (N/A); 1=CLOSED (N/A)
  0x10 SW_SEL_SH reset 0x7000000 — Shielding Switch Control
    [31] BUF_EN
      0=DISABLED (N/A); 1=ENABLED (N/A)
    [27:24] BUF_SEL
    [16] FSP
      0=OPEN (N/A); 1=CLOSED (N/A)
    [14] SPCS3
      0=OPEN (N/A); 1=CLOSED (N/A)
    [12] SPCS1
      0=OPEN (N/A); 1=CLOSED (N/A)
    [10] CBSO
      0=OPEN (N/A); 1=CLOSED (N/A)
    [8] SOMB — Shield OpAmp to AMUXBUSB Switch.
      0=OPEN (N/A); 1=CLOSED (N/A)
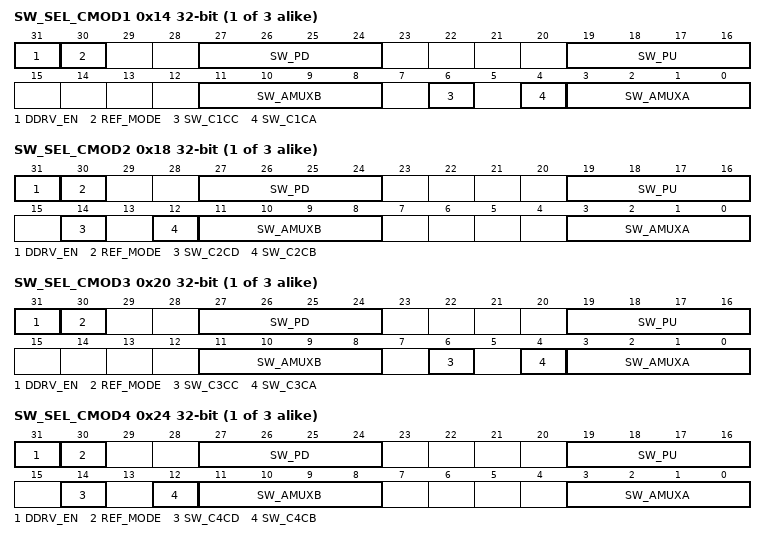
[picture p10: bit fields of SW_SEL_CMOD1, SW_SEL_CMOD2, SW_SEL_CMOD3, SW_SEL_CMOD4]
  0x14 SW_SEL_CMOD1 — CMOD Switch Control 1
    [31] DDRV_EN — CMOD1 digital driver enable in MSCLP specific GPIO. Firmware Rule: When using the digital driver, the GPIO MSCLP analog cannot be used (GPIO port register MSC_ANA.DATAx for port pin x should be set 0).
      0=DISABLED (N/A); 1=ENABLED (N/A)
    [30] REF_MODE — CMOD1 is used as a reference in scenario where CMOD can be re-purposed when not used as a CMOD.
      0=DISABLED (N/A); 1=ENABLED (N/A)
    [27:24] SW_PD — CMOD1 to vssa_q Switch. Firmware Rule: Do not program SW_PU and SW_PD such that they are closed simultaneously.
      values as SW_SEL_CSW[0].SW_PD
    [19:16] SW_PU — CMOD1 to vdda_q Switch. Also drives the MSCLP specific GPIO digital driver (enable controlled by DDRV_EN). Firmware Rule: Do not program SW_PU and SW_PD such that they are closed simultaneously.
      values as SW_SEL_CSW[0].SW_PU
    [11:8] SW_AMUXB — CMOD1 to AMUXBUSB Switch. Switch exists in MSCLP specific GPIO.
      values as SW_SEL_CSW[0].SW_AMUXB
    [6] SW_C1CC — CMOD1 to CSD Bus C Switch. Switch exists in MSCLP hard IP.
      0=OPEN (N/A); 1=CLOSED (N/A)
    [4] SW_C1CA — CMOD1 to CSD Bus A Switch. Switch exists in MSCLP hard IP.
      0=OPEN (N/A); 1=CLOSED (N/A)
    [3:0] SW_AMUXA — CMOD1 to AMUXBUSA Switch. Switch exists in MSCLP specific GPIO.
      values as SW_SEL_CSW[0].SW_AMUXA
  0x18 SW_SEL_CMOD2 — CMOD Switch Control 2
    [31] DDRV_EN — CMOD2 digital driver enable in MSCLP specific GPIO. Firmware Rule: When using the digital driver, the GPIO MSCLP analog cannot be used (GPIO port register MSC_ANA.DATAx for port pin x should be set 0).
      0=DISABLED (N/A); 1=ENABLED (N/A)
    [30] REF_MODE — CMOD2 is used as a reference in scenario where CMOD can be re-purposed when not used as a CMOD.
      0=DISABLED (N/A); 1=ENABLED (N/A)
    [27:24] SW_PD — CMOD2 to vssa_q Switch. Firmware Rule: Do not program SW_PU and SW_PD such that they are closed simultaneously.
      values as SW_SEL_CSW[0].SW_PD
    [19:16] SW_PU — CMOD2 to vdda_q Switch. Also drives the MSCLP specific GPIO digital driver (enable controlled by DDRV_EN). Firmware Rule: Do not program SW_PU and SW_PD such that they are closed simultaneously.
      values as SW_SEL_CSW[0].SW_PU
    [14] SW_C2CD — CMOD2 to CSD Bus D Switch. Switch exists in MSCLP hard IP.
      0=OPEN (N/A); 1=CLOSED (N/A)
    [12] SW_C2CB — CMOD2 to CSD Bus B Switch. Switch exists in MSCLP hard IP.
      0=OPEN (N/A); 1=CLOSED (N/A)
    [11:8] SW_AMUXB — CMOD2 to AMUXBUSB Switch. Switch exists in MSCLP specific GPIO.
      values as SW_SEL_CSW[0].SW_AMUXB
    [3:0] SW_AMUXA — CMOD2 to AMUXBUSA Switch. Switch exists in MSCLP specific GPIO.
      values as SW_SEL_CSW[0].SW_AMUXA
  0x20 SW_SEL_CMOD3 — CMOD Switch Control 3
    [31] DDRV_EN
      0=DISABLED (N/A); 1=ENABLED (N/A)
    [30] REF_MODE — CMOD3 is used as a reference in scenario where CMOD can be re-purposed when not used as a CMOD.
      0=DISABLED (N/A); 1=ENABLED (N/A)
    [27:24] SW_PD — CMOD3 to vssa_q Switch. Firmware Rule: Do not program SW_PU and SW_PD such that they are closed simultaneously.
      values as SW_SEL_CSW[0].SW_PD
    [19:16] SW_PU — CMOD3 to vdda_q Switch. Also drives the MSC specific GPIO digital driver (enable controlled by DDRV_EN). Firmware Rule: Do not program SW_PU and SW_PD such that they are closed simultaneously.
      values as SW_SEL_CSW[0].SW_PU
    [11:8] SW_AMUXB — CMOD3 to AMUXBUSB Switch.
      values as SW_SEL_CSW[0].SW_AMUXB
    [6] SW_C3CC — CMOD3 to CSD Bus C Switch.
      0=OPEN (N/A); 1=CLOSED (N/A)
    [4] SW_C3CA — CMOD3 to CSD Bus A Switch.
      0=OPEN (N/A); 1=CLOSED (N/A)
    [3:0] SW_AMUXA — CMOD3 to AMUXBUSA Switch.
      values as SW_SEL_CSW[0].SW_AMUXA
  0x24 SW_SEL_CMOD4 — CMOD Switch Control 4
    [31] DDRV_EN
      0=DISABLED (N/A); 1=ENABLED (N/A)
    [30] REF_MODE
      0=DISABLED (N/A); 1=ENABLED (N/A)
    [27:24] SW_PD — CMOD4 to vssa_q Switch. Firmware Rule: Do not program SW_PU and SW_PD such that they are closed simultaneously.
      values as SW_SEL_CSW[0].SW_PD
    [19:16] SW_PU — CMOD4 to vdda_q Switch. Also drives the MSC specific GPIO digital driver (enable controlled by DDRV_EN). Firmware Rule: Do not program SW_PU and SW_PD such that they are closed simultaneously.
      values as SW_SEL_CSW[0].SW_PU
    [14] SW_C4CD — CMOD4 to CSD Bus D Switch.
      0=OPEN (N/A); 1=CLOSED (N/A)
    [12] SW_C4CB — CMOD4 to CSD Bus B Switch.
      0=OPEN (N/A); 1=CLOSED (N/A)
    [11:8] SW_AMUXB — CMOD4 to AMUXBUSB Switch.
      values as SW_SEL_CSW[0].SW_AMUXB
    [3:0] SW_AMUXA — CMOD4 to AMUXBUSA Switch.
      values as SW_SEL_CSW[0].SW_AMUXA
0x2000 SNS group — Sensor Configuration Structure (clk_imo_msc domain)
  {0x0+4j} SENSOR_DATA[{j}] (j=0..1023) — Sensor Configuration Storage
    [31:0] DATA — Local IP storage to support per-sensor configuration and results for AS-MS/LP-AoS mode. The per sensor registers all have the prefix SNS_* in the SNS_STRUCTLP register tab. Firmware Rule: Firmware must program the following registers in a manner to allow for SENSOR_DATA to be used for both purposes (configuration and result). Sensor configuration: FRAME_CFG_START_ADDR is set by software to indicate to hardware where the first sensor scan configuration structure exists in SENSOR_DATA to start processing a frame (typically set to 0x0). The size of each configuration structure depends on what software sets for CFG_OFFSET (see description of this register for more details). Autonomous scanning will execute sequential structures (size defined by CFG_OFFSET) until it encounters a structure with SNS_CTL.LAST set. This defines the end of the frame. Sensor results: FRAME_RES_START_ADDR is set by software to define the base address (in 32-bit words) of the result FIFO (where the frame raw counts are stored). The depth of the FIFO is inferred by the setting for FRAME_RES_START_ADDR and the size of the memory integrated by the IP. For example if 1kB is available, there are 256x 32-bit entries in SENSOR_DATA (0->255). If FRAME_RES_START_ADDR is set to 224, then the FIFO depth = 255-224+1 = 32. The result data is directly accessible by firmware via SENSOR_DATA (with an understanding of FRAME_RES_START_ADDR to know which index in SENSOR_DATA to access). The result FIFO can also be accessed as a FIFO via RESULT_FIFO_RD, which always points to the head of the FIFO (as tracked by hardware) and a read to this register pops the top result off this FIFO. See description of RESULT_FIFO_RD for details. Note that depending on the size of the SRAM macro integrated with the IP, and the amount of sensors being scanned (and amount of autonomous configuration required) - it is possible to have multiple sets of frame configuration and/or have the result FIFO sized to store multiple frames of data.
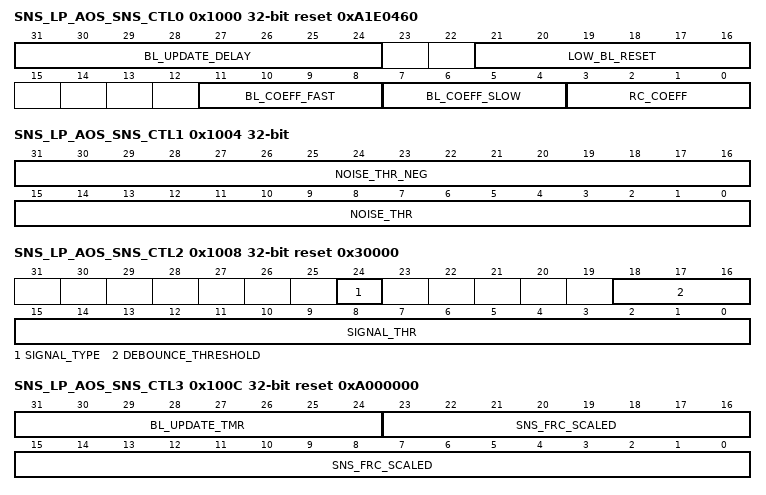
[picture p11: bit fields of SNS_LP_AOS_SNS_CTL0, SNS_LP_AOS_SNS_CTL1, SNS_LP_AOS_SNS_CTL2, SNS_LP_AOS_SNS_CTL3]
  0x1000 SNS_LP_AOS_SNS_CTL0 reset 0xA1E0460 — LP-AoS Sensor Control 0
    [31:24] BL_UPDATE_DELAY
    [21:16] LOW_BL_RESET
    [11:8] BL_COEFF_FAST
      1=MIN (N/A)
    [7:4] BL_COEFF_SLOW
      1=MIN (N/A)
    [3:0] RC_COEFF
      8=MAX (N/A)
  0x1004 SNS_LP_AOS_SNS_CTL1 — LP-AoS Sensor Control 1
    [31:16] NOISE_THR_NEG, [15:0] NOISE_THR
  0x1008 SNS_LP_AOS_SNS_CTL2 reset 0x30000 — LP-AoS Sensor Control 2
    [24] SIGNAL_TYPE
      0=POSITIVE (N/A); 1=NEGATIVE (N/A)
    [18:16] DEBOUNCE_THRESHOLD
    [15:0] SIGNAL_THR
  0x100C SNS_LP_AOS_SNS_CTL3 reset 0xA000000 — LP-AoS Sensor Control 3
    [31:24] BL_UPDATE_TMR, [23:0] SNS_FRC_SCALED
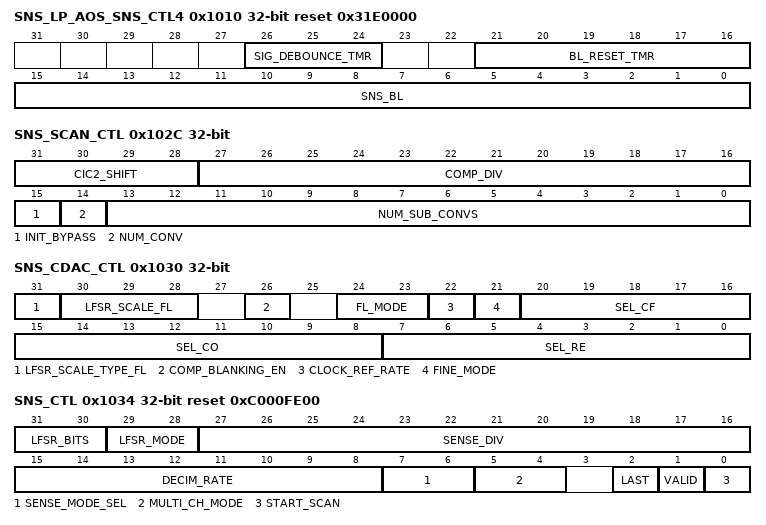
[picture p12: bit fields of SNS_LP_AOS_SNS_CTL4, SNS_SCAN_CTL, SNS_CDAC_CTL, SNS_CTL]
  0x1010 SNS_LP_AOS_SNS_CTL4 reset 0x31E0000 — LP-AoS Sensor Control 4
    [26:24] SIG_DEBOUNCE_TMR, [21:16] BL_RESET_TMR, [15:0] SNS_BL
  0x1014 SNS_SW_SEL_CSW_HI_MASK2 — CAPSENSE Sensor Switch Function Select High Mask 2
    [31:0] FUNC_MASK
  0x1018 SNS_SW_SEL_CSW_HI_MASK1 — CAPSENSE Sensor Switch Function Select High Mask 1
    [31:0] FUNC_MASK
  0x101C SNS_SW_SEL_CSW_HI_MASK0 — CAPSENSE Sensor Switch Function Select High Mask 0
    [31:0] FUNC_MASK
  0x1020 SNS_SW_SEL_CSW_LO_MASK2 — CAPSENSE Sensor Switch Function Select Low Mask 2
    [31:0] FUNC_MASK
  0x1024 SNS_SW_SEL_CSW_LO_MASK1 — CAPSENSE Sensor Switch Function Select Low Mask 1
    [31:0] FUNC_MASK
  0x1028 SNS_SW_SEL_CSW_LO_MASK0 — CAPSENSE Sensor Switch Function Select Low Mask 0
    [31:0] FUNC_MASK
  0x102C SNS_SCAN_CTL — Sensor Scan Control
    [31:28] CIC2_SHIFT
    [27:16] COMP_DIV — The ratio (minus 1) of clk_comp::clk_mod. Notes for tuning: Fs = Fmod / Kref Fcomp = Kcomp * Fs MSCLP MMIO provides: Kref = (SENSE_DIV+1) Fs = Fmod/(SENSE_DIV+1) Fcomp = Fmod / (COMP_DIV+1) Therefore: Kcomp = Fmod/[Fs*(COMP_DIV+1)] Kcomp = (SENSE_DIV+1)/(COMP_DIV+1) Firmware Rule: It is expected that Kcomp be programmed as an integer. Anything else is considered a mis-programming.
    [15] INIT_BYPASS
      0=DISABLED (N/A); 1=ENABLED (N/A)
    [14] NUM_CONV
      0=ONE (N/A); 1=TWO (N/A)
    [13:0] NUM_SUB_CONVS
  0x1030 SNS_CDAC_CTL — Sensor CAPDAC Control
    [31] LFSR_SCALE_TYPE_FL
      0=RIGHT (N/A); 1=LEFT (N/A)
    [30:28] LFSR_SCALE_FL
      6=MAX (N/A)
    [26] COMP_BLANKING_EN — Compensation blanking control. Type of blanking controlled by COMP_BLANKING_MODE. The time window in which these effects apply depend on the following. When enabled and in Direct Clock and Spread Spectrum mode (LFSR_MODE): 2-Phase: 50 percent Comp: PH0: Enable Comp for (SENSE_DIV+1)/4 (this will be 0.5 of Ph0 phase) PH1: Enable Comp for (SENSE_DIV+1)/4 (this will be 0.5 of Ph1 phase) 25 percent Comp: PH0: Enable Comp for (SENSE_DIV+1)/8 (this will be 0.25 of Ph0 phase) PH1: Enable Comp for (SENSE_DIV+1)/8 (this will be 0.25 of Ph1 phase) 4-Phase: 50 percent Comp: PH1: Enable Comp for (SENSE_DIV+1)/4 (this will be Full of Ph1 phase) PH3: Enable Comp for (SENSE_DIV+1)/4 (this will be Full of Ph3 phase) 25 percent Comp: PH1: Enable Comp for (SENSE_DIV+1)/8 (this will be 0.5 of Ph1 phase) PH3: Enable Comp for (SENSE_DIV+1)/8 (this will be 0.5 of Ph3 phase) Note that in Spread Spectrum mode, if the ph* where compensation is on shrinks from the nominal. So, if we have 50 percent compensation the ph can shrink to be shorter than (SENSE_DIV+1)/4. So for example if ph1 shrinks, this will mean that compensation stays on a bit into ph2. This is OK. When enabled and in PRS mode (LFSR_MODE): 2-Phase PRS: 50 percent Comp: PH0: Enable Comp for (SENSE_DIV+1) (this will be 0.5 of AVG Ph0 and All of MIN Ph0) PH1: Enable Comp for (SENSE_DIV+1) (this will be 0.5 of AVG Ph1 and All of MIN Ph1) 25 percent Comp: PH0: Enable Comp for (SENSE_DIV+1)/2 (this will be 0.25 of AVG Ph0 and 0.5 of Min Ph0) PH1: Enable Comp for (SENSE_DIV+1)/2 (this will be 0.25 of AVG Ph1 and 0.5 of Min Ph1) 4-Phase PRS: 50 percent Comp: PH1: Enable Comp for (SENSE_DIV+1)*2 (this will be All of AVG Ph1 and 2x of Min Ph1 or All of Min Ph1+Min Ph2) PH3: Enable Comp for (SENSE_DIV+1)*2 (this will be All of AVG Ph3 and 2x of Min Ph3 or All of Min Ph3+Min Ph0) 25 percent Comp: PH1: Enable Comp for (SENSE_DIV+1) (this will be 0.5 of AVG Ph1 and All of Min Ph1) PH3: Enable Comp for (SENSE_DIV+1) (this will be 0.5 of AVG Ph3 and All of Min Ph3)
      0=DISABLED (N/A); 1=ENABLED (N/A)
    [24:23] FL_MODE — Dither/Flatspot LFSR enable control.
      0=DISABLED (N/A); 1=DITHER (N/A); 2=OFFSET (N/A)
    [22] CLOCK_REF_RATE
      0=CLK_MOD (N/A); 1=HALF_CLK_MOD (N/A)
    [21] FINE_MODE
      0=REFERENCE (N/A); 1=COMPENSATION (N/A)
    [20:16] SEL_CF — Select value for Fine CAPDAC size.
    [15:8] SEL_CO — Select value for Compensation CAPDAC size.
    [7:0] SEL_RE — Select value for Reference CAPDAC size.
  0x1034 SNS_CTL reset 0xC000FE00 — Sense Control and Command Register
    [31:30] LFSR_BITS
      0=2B (Use 2 bits: range = [-2,1]); 1=3B (Use 3 bits: range = [-4,3]); 2=4B (Use 4 bits: range = [-8,7]); 3=5B (Use 5 bits: range = [-16,15] (default))
    [29:28] LFSR_MODE
      0=DIRECT_CLOCK (N/A); 1=SPREAD_SPECTRUM (N/A); 2=PRS (N/A)
    [27:16] SENSE_DIV
    [15:8] DECIM_RATE
    [7:6] SENSE_MODE_SEL — Sense mode register structure selection. This field allows quick change between registers that influence sense mode. This register selects which structure is currently 'live' and used by the IP. These registers are captured in MODE_STRUCT.
      {v}=SENSE_MODE_{v} (Use MODE_STRUCT[{v}].) (v=0..3)
    [5:4] MULTI_CH_MODE
      0=OFF (N/A); 1=INTERNAL (N/A); 2=EXTERNAL (N/A)
    [2] LAST
    [1] VALID
    [0] START_SCAN — Start the MSCLP sequencer scan process. The sequencer will clear this bit when it is done. Depending on the mode the sequencer is done when all NUM_SAMPLES for this scan have been accumulated, or if the sequencer is reset.
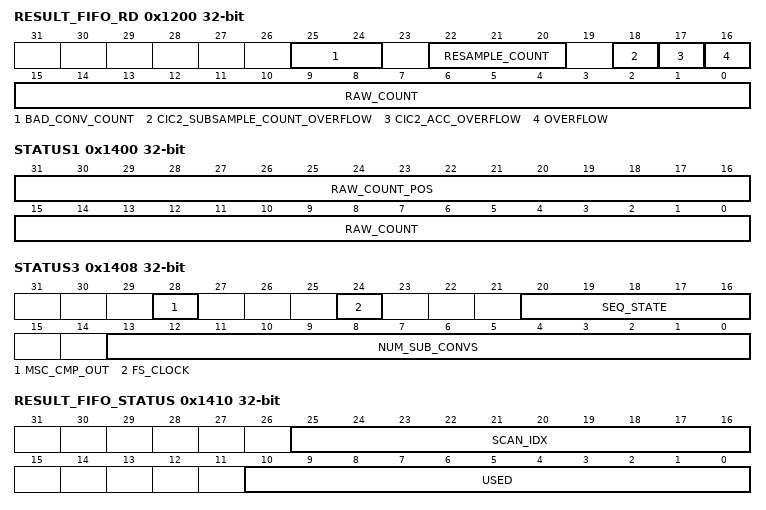
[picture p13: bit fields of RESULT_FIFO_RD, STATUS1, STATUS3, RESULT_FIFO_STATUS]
  0x1200 RESULT_FIFO_RD ro — Result FIFO Pointer
    [25:24] BAD_CONV_COUNT, [22:20] RESAMPLE_COUNT, [18] CIC2_SUBSAMPLE_COUNT_OVERFLOW, [17] CIC2_ACC_OVERFLOW, [16] OVERFLOW, [15:0] RAW_COUNT
  0x1400 STATUS1 ro — General Status Register 1
    [31:16] RAW_COUNT_POS, [15:0] RAW_COUNT
  0x1404 STATUS2 ro — General Status Register 2
    [15:0] DEBUG_CONV_COUNT
  0x1408 STATUS3 ro — General Status Register 3
    [28] MSC_CMP_OUT
    [24] FS_CLOCK
    [20:16] SEQ_STATE — MSCLP Sequencer FSM state.
      0=IDLE (N/A); 1=WAIT_DMA_WRITE (N/A); 2=LOAD_CONFIG (N/A); 3=WAIT_SCAN_START (N/A); 4=ASSERT_RDY (N/A); 5=WAIT_CONSENSUS (N/A); 6=INIT_CMOD (N/A); 7=INIT_SHORT (N/A); 8=PRO_OFFSET (N/A); 9=PRO_DUMMY (N/A); 10=PRO_WAIT (N/A); 11=SUB_CONV (N/A); 12=EPILOGUE (N/A); 13=WAIT_DMA_READ_NEW_SAMPLE (N/A); 14=WAIT_DMA_READ_EOF (N/A); 15=POST_SCAN (N/A); 16=POST_EPI (N/A)
    [13:0] NUM_SUB_CONVS
  0x140C STATUS4 ro — General Status Register 4
    [8:0] NUM_CIC2_SUB_SAMPLES
  0x1410 RESULT_FIFO_STATUS ro
    [25:16] SCAN_IDX, [10:0] USED
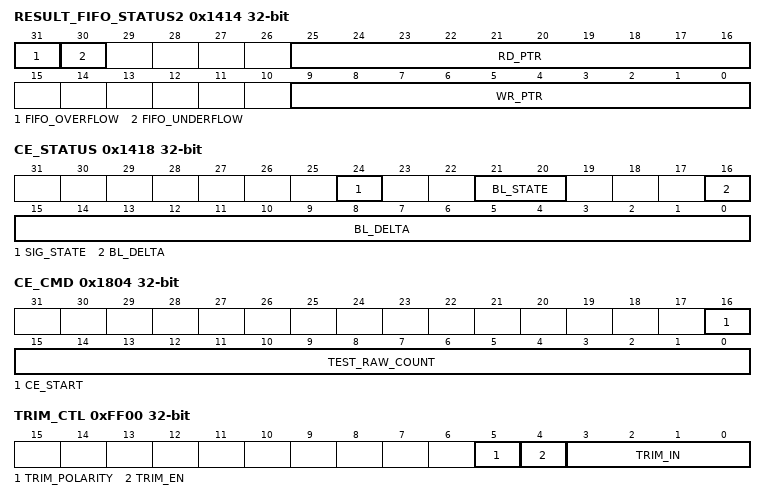
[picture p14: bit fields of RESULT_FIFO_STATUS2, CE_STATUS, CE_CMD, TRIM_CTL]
  0x1414 RESULT_FIFO_STATUS2 ro
    [31] FIFO_OVERFLOW, [30] FIFO_UNDERFLOW, [25:16] RD_PTR, [9:0] WR_PTR
  0x1418 CE_STATUS ro — Channel Engine Status
    [24] SIG_STATE
    [21:20] BL_STATE
      0=INIT (Initialise baseline to raw count.); 1=UPDATE_SLOW (Slow baseline update when raw count minus baseline exceeds sensor noise threshold.); 2=UPDATE_FAST (Fast baseline update when baseline minus raw count exceeds sensor negative noise threshold.)
    [16:0] BL_DELTA
  0x141C BRIDGE_STATUS ro reset 0x1 — AHB2AHB Bridge Status
    [0] READY
  0x1800 FRAME_CMD — Frame Command Register
    [0] START_FRAME — Start the MSCLP sequencer frame process. Note that a rising edge on this bit also creates a 4x cycle clk_msc pulse on the msc_ext_frm_start_out signal (when EXT_FRAME_START_MODE = DISABLED). The corresponding msc_ext_frm_start_out_en is controlled by CTL.ENABLED. Sequencer FSM clears this bit on egress from IDLE. If START_FRAME is set by firmware when FSM is not in IDLE, the hardware must hold the bit set to allow for 'pending' frame behaviour. Firmware Rule: Note if FRAME_CMD is used in a multi-channel scenario care must be taken by firmware not to excessively delay FRAME_CMD to each individual channel. If not, a window exists where the first channel that sees FRAME_CMD can reach the WAIT_CONSENSUS state and mistakenly believe all channels are ready for lockstep scanning when the reality is the other channels are still in IDLE and indicating ready because they haven't been initiated yet.
  0x1804 CE_CMD — Channel Engine Command
    [16] CE_START, [15:0] TEST_RAW_COUNT
  0x1808 FIFO_CMD — FIFO Command
    [0] FIFO_RESET
  0x1C00 CE_INIT_CTL — Channel Engine Initialisation Control
    [0] SENSOR_INIT
      0=FW_INIT (N/A); 1=HW_INIT (N/A)
0xFF00 TRIM_CTL — Trim Control
  [5] TRIM_POLARITY
  [4] TRIM_EN
    0=DISABLED (N/A); 1=ENABLED (N/A)
  [3:0] TRIM_IN
0xFF04 CLK_IMO_TRIM1 reset 0x80 — Local IMO Trim Register 1
  [7:0] OFFSET
0xFF08 CLK_IMO_TRIM2 — Local IMO Trim Register 2
  [2:0] FSOFFSET
0xFF0C CLK_IMO_TRIM3 reset 0x2 — Local IMO Trim Register 3
  [1:0] TCTRIM
0xFF10 PWR_BG_TRIM1 reset 0x10 — Bandgap Trim Register 1
  [5:0] REF_VTRIM
0xFF14 PWR_BG_TRIM2 reset 0x1C — Bandgap Trim Register 2
  [5:0] REF_ITRIM
0xFF18 PWR_BG_TRIM3 — Bandgap Trim Register 3
  [3:0] REF_TCTRIM
